VERSION ""

NS_ :

BS_:

BU_: Logger

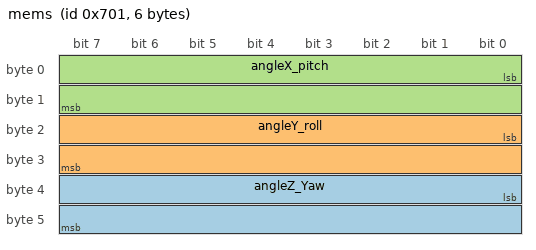
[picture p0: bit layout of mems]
BO_ 1793 mems: 6 Logger
 SG_ angleZ_Yaw : 32|16@1- (1,0) [-32768|32767] "degree" Vector__XXX
 SG_ angleY_roll : 16|16@1- (1,0) [-32768|32767] "degree" Vector__XXX
 SG_ angleX_pitch : 0|16@1- (1,0) [-32768|32767] "degree" Vector__XXX

BO_ 1794 gps: 8 Logger
 SG_ longitude : 32|32@1- (1,0) [-180|180] "" Vector__XXX
 SG_ latitude : 0|32@1- (1,0) [-90|90] "" Vector__XXX

BA_DEF_  "BusType" STRING ;
BA_DEF_DEF_  "BusType" "";
BA_ "BusType" "CAN";
SIG_VALTYPE_ 1794 longitude : 1;
SIG_VALTYPE_ 1794 latitude : 1;
